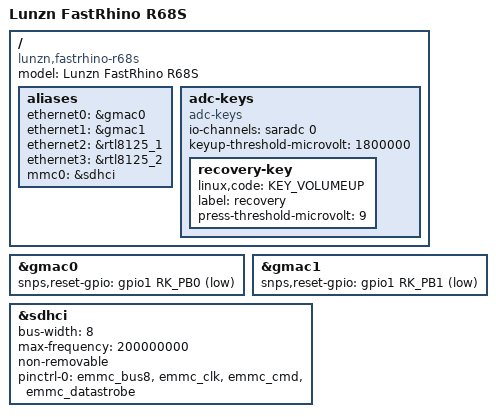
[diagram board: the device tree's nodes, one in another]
// SPDX-License-Identifier: (GPL-2.0+ OR MIT)

#include "rk3568-fastrhino-r6xs.dtsi"

/ {
	model = "Lunzn FastRhino R68S";
	compatible = "lunzn,fastrhino-r68s", "rockchip,rk3568";

	aliases {
		ethernet0 = &gmac0;
		ethernet1 = &gmac1;
		ethernet2 = &rtl8125_1;
		ethernet3 = &rtl8125_2;
		mmc0 = &sdhci;
	};

	adc-keys {
		compatible = "adc-keys";
		io-channels = <&saradc 0>;
		io-channel-names = "buttons";
		keyup-threshold-microvolt = <1800000>;
		u-boot,dm-spl;
		status = "okay";

		recovery-key {
			u-boot,dm-spl;
			// u-boot needs this code to be happy
			linux,code = <KEY_VOLUMEUP>;
			label = "recovery";
			press-threshold-microvolt = <9>;
		};
	};
};

&gmac0 {
	snps,reset-gpio = <&gpio1 RK_PB0 GPIO_ACTIVE_LOW>;
	status = "okay";
};

&gmac1 {
	snps,reset-gpio = <&gpio1 RK_PB1 GPIO_ACTIVE_LOW>;
	status = "okay";
};

&sdhci {
	bus-width = <8>;
	max-frequency = <200000000>;
	non-removable;
	pinctrl-names = "default";
	pinctrl-0 = <&emmc_bus8 &emmc_clk &emmc_cmd &emmc_datastrobe>;
	status = "okay";
};
